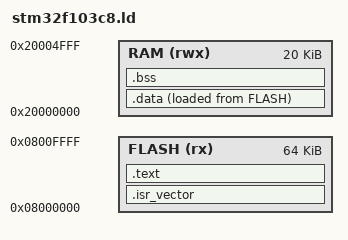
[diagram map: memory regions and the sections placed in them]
ENTRY(Reset_Handler)

MEMORY
{
    FLASH (rx)  : ORIGIN = 0x08000000, LENGTH = 64K
    RAM   (rwx) : ORIGIN = 0x20000000, LENGTH = 20K
}

_estack = ORIGIN(RAM) + LENGTH(RAM);

SECTIONS
{
    .isr_vector :
    {
        . = ALIGN(4);

        KEEP(*(.isr_vector))

        . = ALIGN(4);
    } > FLASH

    .text :
    {
        . = ALIGN(4);

        *(.text)
        *(.text*)
        *(.rodata)
        *(.rodata*)

        . = ALIGN(4);
        _etext = .;
    } > FLASH

    _sidata = LOADADDR(.data);

    .data :
    {
        . = ALIGN(4);
        _sdata = .;

        *(.data)
        *(.data*)

        . = ALIGN(4);
        _edata = .;
    } > RAM AT > FLASH

    .bss (NOLOAD) :
    {
        . = ALIGN(4);
        _sbss = .;

        *(.bss)
        *(.bss*)
        *(COMMON)

        . = ALIGN(4);
        _ebss = .;
    } > RAM

    /DISCARD/ :
    {
        *(.comment)
        *(.note*)
    }
}

/*
 * 59 vectors x 4 bytes = 236 bytes.
 */
ASSERT(
    SIZEOF(.isr_vector) == 236,
    "STM32F103C8 vector table must contain 59 entries"
)

ASSERT(
    _estack == 0x20005000,
    "Incorrect STM32F103C8 stack-top address"
)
